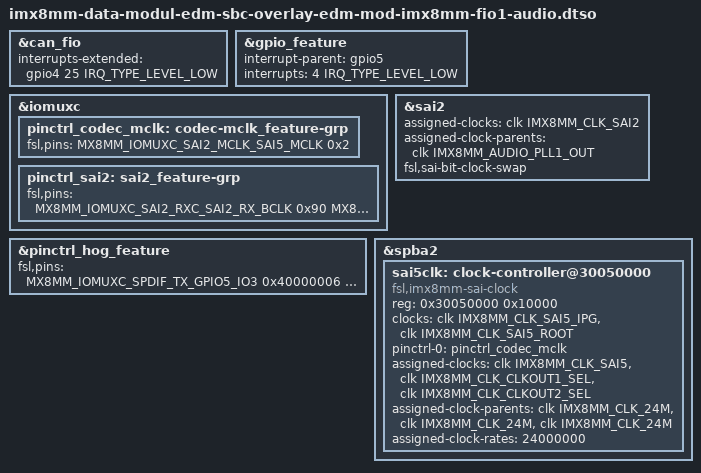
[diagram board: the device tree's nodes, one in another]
// SPDX-License-Identifier: (GPL-2.0+ OR MIT)
/*
 * Copyright 2024-2026 Marek Vasut
 */
/dts-v1/;
/plugin/;

#include <dt-bindings/clock/imx8mm-clock.h>

#include "imx8mm-pinfunc.h"
#include "imx8mm-data-modul-edm-sbc-overlay-edm-mod-imx8mm-fio1-audio.dtsi"

&can_fio {
	interrupts-extended = <&gpio4 25 IRQ_TYPE_LEVEL_LOW>;
};

&gpio_feature {
	interrupt-parent = <&gpio5>;
	interrupts = <4 IRQ_TYPE_LEVEL_LOW>;
};

&iomuxc {
	pinctrl_codec_mclk: codec-mclk_feature-grp {
		fsl,pins = <
			/* GPIO4_IO27 */
			MX8MM_IOMUXC_SAI2_MCLK_SAI5_MCLK		0x2
		>;
	};

	pinctrl_sai2: sai2_feature-grp {
		fsl,pins = <
			MX8MM_IOMUXC_SAI2_RXC_SAI2_RX_BCLK		0x90
			MX8MM_IOMUXC_SAI2_TXD0_SAI2_TX_DATA0		0x96
			MX8MM_IOMUXC_SAI2_RXD0_SAI2_RX_DATA0		0x90
			MX8MM_IOMUXC_SAI2_TXFS_SAI2_TX_SYNC		0x96
		>;
	};
};

&pinctrl_hog_feature {
	fsl,pins = <
		/* GPIO5_IO03 */
		MX8MM_IOMUXC_SPDIF_TX_GPIO5_IO3				0x40000006
		/* GPIO5_IO04 */
		MX8MM_IOMUXC_SPDIF_RX_GPIO5_IO4				0x40000006

		/* CAN_INT# */
		MX8MM_IOMUXC_SAI2_TXC_GPIO4_IO25			0x40000090
	>;
};

&sai2 {
	assigned-clocks = <&clk IMX8MM_CLK_SAI2>;
	assigned-clock-parents = <&clk IMX8MM_AUDIO_PLL1_OUT>;
	fsl,sai-bit-clock-swap;
};

&spba2 {
	#address-cells = <1>;
	#size-cells = <1>;

	sai5clk: clock-controller@30050000 {	/* SAI5 */
		compatible = "fsl,imx8mm-sai-clock", "fsl,imx8mq-sai-clock";
		reg = <0x30050000 0x10000>;
		#clock-cells = <1>;
		clocks = <&clk IMX8MM_CLK_SAI5_IPG>,
			 <&clk IMX8MM_CLK_SAI5_ROOT>;
		clock-names = "bus", "mclk1";
		pinctrl-names = "default";
		pinctrl-0 = <&pinctrl_codec_mclk>;
		assigned-clocks = <&clk IMX8MM_CLK_SAI5>,
				  <&clk IMX8MM_CLK_CLKOUT1_SEL>,
				  <&clk IMX8MM_CLK_CLKOUT2_SEL>;
		assigned-clock-parents = <&clk IMX8MM_CLK_24M>,
					 <&clk IMX8MM_CLK_24M>,
					 <&clk IMX8MM_CLK_24M>;
		assigned-clock-rates = <24000000>;
	};
};
